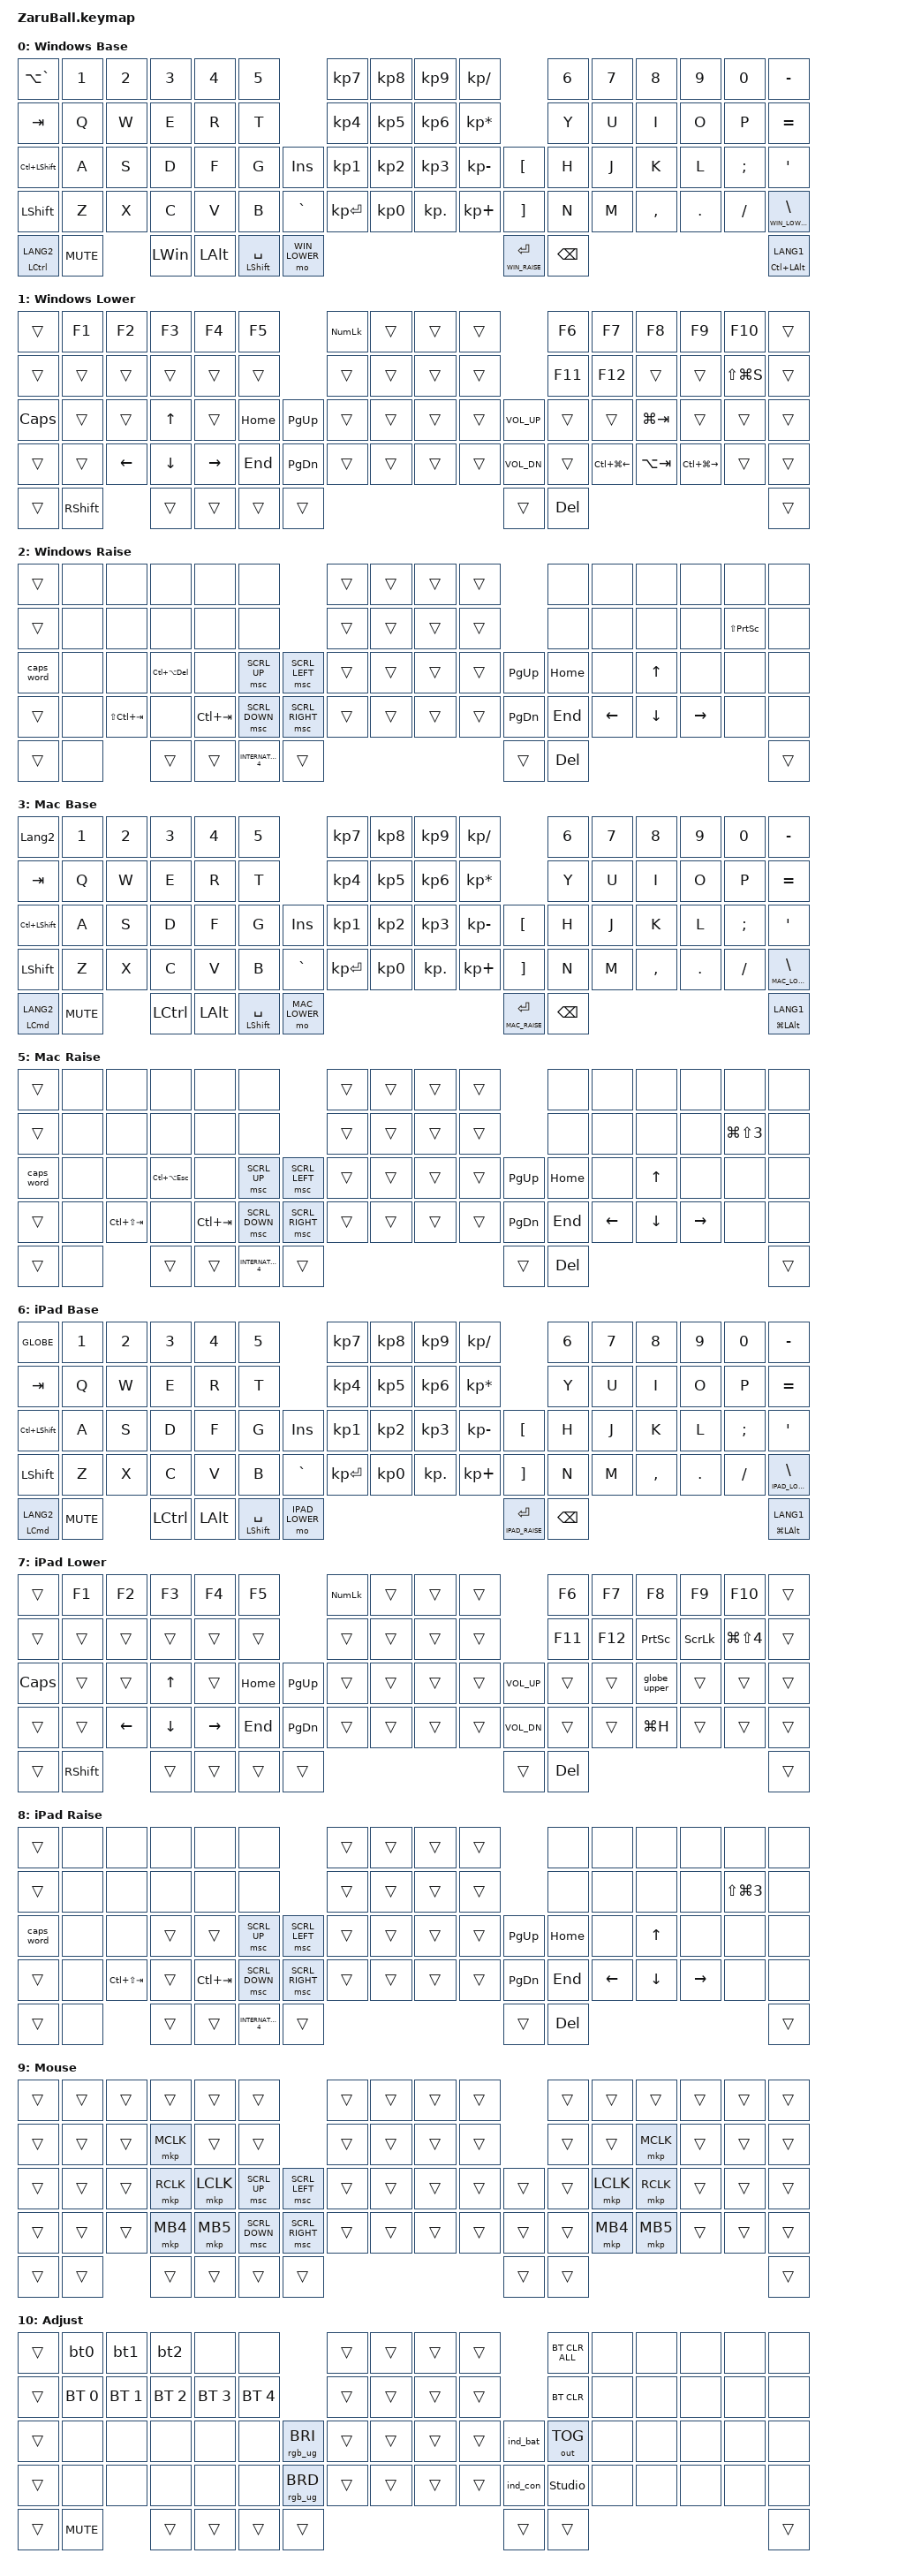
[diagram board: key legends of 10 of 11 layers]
//#include <dt-bindings/zmk/mouse.h>

#include <behaviors/rgbled_widget.dtsi>
#include <input/processors.dtsi>
#include <dt-bindings/zmk/input_transform.h>
#include <behaviors.dtsi>
#include <dt-bindings/zmk/bt.h>
#include <dt-bindings/zmk/keys.h>
#include <dt-bindings/zmk/outputs.h>
#include <dt-bindings/zmk/pointing.h>
#include <dt-bindings/zmk/rgb.h>

// Define LAYER

#define WIN_BASE    0
#define WIN_LOWER   1
#define WIN_RAISE   2
#define MAC_BASE    3
#define MAC_LOWER   4
#define MAC_RAISE   5
#define IPAD_BASE   6
#define IPAD_LOWER  7
#define IPAD_RAISE  8
#define MOUSE       9
#define ADJUST      10

// スクロール量の設定

#define ZMK_POINTING_DEFAULT_SCRL_VAL 100

/ {
    conditional_layers { compatible = "zmk,conditional-layers"; };
};

&trackball_listener {
    input-processors = <
                         &zip_xy_transform (INPUT_TRANSFORM_XY_SWAP | INPUT_TRANSFORM_Y_INVERT | INPUT_TRANSFORM_X_INVERT)
                         &zip_temp_layer MOUSE 100000
    >;

    scroller {
        layers = <WIN_LOWER WIN_RAISE MAC_LOWER MAC_RAISE IPAD_LOWER IPAD_RAISE ADJUST>;
        input-processors = <
                            &zip_xy_transform (INPUT_TRANSFORM_XY_SWAP | INPUT_TRANSFORM_X_INVERT)
                            &zip_xy_scaler 1 9
                            &zip_xy_to_scroll_mapper
        >;
    };
};

&mkp_input_listener { input-processors = <&zip_temp_layer MOUSE 250>; };

// You can find key number by entering config/info.json into https://zmk-physical-layout-converter.streamlit.app/

&zip_temp_layer {
    require-prior-idle-ms = <200>;
    excluded-positions = <
        19 // E
        28 // I
        35 // D
        36 // F
        37 // G
        38 // INS
        45 // J
        46 // K
        53 // C
        54 // V
        55 // B
        56 // GRAVE
        63 // M
    >;
};

/ {
    behaviors {
        // スクロール用のbehaviorの設定

        scroll_down_up: behavior_sensor_rotate_mouse_wheel_down_up {
            compatible = "zmk,behavior-sensor-rotate";
            #sensor-binding-cells = <0>;
            bindings = <&msc SCRL_DOWN>, <&msc SCRL_UP>;

            tap-ms = <20>; // スクロールのタップ時間
        };

        // Customed Hold-Tap for SandS

        SandS: SandS {
            compatible = "zmk,behavior-hold-tap";
            #binding-cells = <2>;
            flavor = "tap-unless-interrupted";
            tapping-term-ms = <500>;
            quick-tap-ms = <500>;
            bindings = <&kp>, <&kp>;

            display-name = "SandS";
        };

        // Ref: https://zenn.dev/shakupan/articles/261ce435251607

        tog_on: toggle_layer_on_only {
            compatible = "zmk,behavior-toggle-layer";
            #binding-cells = <1>;
            display-name = "Toggle Layer On";
            toggle-mode = "on";
        };

        tog_off: toggle_layer_off_only {
            compatible = "zmk,behavior-toggle-layer";
            #binding-cells = <1>;
            display-name = "Toggle Layer Off";
            toggle-mode = "off";
        };
    };
};

/ {
    macros {
        bt0: bt0 {
            compatible = "zmk,behavior-macro";
            #binding-cells = <0>;
            bindings =
                <&tog_off MAC_BASE &tog_off IPAD_BASE>,
                <&macro_wait_time 200>,
                <&bt BT_SEL 0>;

            label = "BT0";
            wait-ms = <200>;
        };

        bt1: bt1 {
            compatible = "zmk,behavior-macro";
            #binding-cells = <0>;
            bindings =
                <&tog_off MAC_BASE &tog_off IPAD_BASE>,
                <&macro_wait_time 200>,
                <&bt BT_SEL 1>,
                <&macro_wait_time 500>,
                <&tog_on MAC_BASE>;

            label = "BT1";
            wait-ms = <200>;
        };

        bt2: bt2 {
            compatible = "zmk,behavior-macro";
            #binding-cells = <0>;
            bindings =
                <&tog_off MAC_BASE &tog_off IPAD_BASE>,
                <&macro_wait_time 200>,
                <&bt BT_SEL 2>,
                <&macro_wait_time 500>,
                <&tog_on IPAD_BASE>;

            label = "BT2";
            wait-ms = <200>;
        };

        lalt_grave: lalt_grave {
            compatible = "zmk,behavior-macro";
            #binding-cells = <0>;
            bindings =
                <&kt LEFT_ALT>,
                <&macro_wait_time 10>,
                <&kp GRAVE &kt LEFT_ALT>;

            label = "LALT_GRAVE";
        };

        globe_upper: globe_upper {
            compatible = "zmk,behavior-macro";
            #binding-cells = <0>;
            bindings =
                <&kt GLOBE>,
                <&macro_wait_time 10>,
                <&kp UP_ARROW &kt GLOBE>;

            label = "GLOBE_UPPER";
        };
    };
};

/ {
    combos {
        compatible = "zmk,combos";

        ESCandToAdjustLayer {
            bindings = <&lt ADJUST ESC>;
            key-positions = <73 74>;
        };
    };

    keymap {
        compatible = "zmk,keymap";

        win_base {
            display-name = "Windows Base";
            sensor-bindings = <&scroll_down_up>;
            bindings = <
&kp LA(GRAVE)       &kp N1      &kp N2  &kp N3    &kp N4        &kp N5                                    &kp KP_N7     &kp KP_N8  &kp KP_N9   &kp KP_DIVIDE                         &kp NUMBER_6  &kp N7  &kp N8     &kp N9   &kp N0    &kp MINUS
&kp TAB             &kp Q       &kp W   &kp E     &kp R         &kp T                                     &kp KP_N4     &kp KP_N5  &kp KP_N6   &kp KP_MULTIPLY                       &kp Y         &kp U   &kp I      &kp O    &kp P     &kp EQUAL
&kp LC(LEFT_SHIFT)  &kp A       &kp S   &kp D     &kp F         &kp G                    &kp INS          &kp KP_N1     &kp KP_N2  &kp KP_N3   &kp KP_MINUS       &kp LEFT_BRACKET   &kp H         &kp J   &kp K      &kp L    &kp SEMI  &kp APOS
&kp LSHFT           &kp Z       &kp X   &kp C     &kp V         &kp B                    &kp GRAVE        &kp KP_ENTER  &kp KP_N0  &kp KP_DOT  &kp KP_PLUS        &kp RIGHT_BRACKET  &kp N         &kp M   &kp COMMA  &kp DOT  &kp FSLH  &lt WIN_LOWER BACKSLASH
&SandS LCTRL LANG2  &kp C_MUTE          &kp LWIN  &kp LEFT_ALT  &SandS LEFT_SHIFT SPACE  &mo WIN_LOWER                                                            &lt WIN_RAISE RET  &kp BSPC                                            &SandS LC(LEFT_ALT) LANG1
            >;
        };

        win_lower {
            display-name = "Windows Lower";
            sensor-bindings = <&inc_dec_kp C_VOL_UP C_VOL_DN>;
            bindings = <
&trans    &kp F1     &kp F2    &kp F3    &kp F4     &kp F5                 &kp KP_NUMLOCK  &trans  &trans  &trans                  &kp F6   &kp F7                  &kp F8       &kp F9                   &kp F10        &trans
&trans    &trans     &trans    &trans    &trans     &trans                 &trans          &trans  &trans  &trans                  &kp F11  &kp F12                 &trans       &trans                   &kp LS(LG(S))  &trans
&kp CAPS  &trans     &trans    &kp UP    &trans     &kp HOME  &kp PG_UP    &trans          &trans  &trans  &trans    &kp C_VOL_UP  &trans   &trans                  &kp LG(TAB)  &trans                   &trans         &trans
&trans    &trans     &kp LEFT  &kp DOWN  &kp RIGHT  &kp END   &kp PG_DN    &trans          &trans  &trans  &trans    &kp C_VOL_DN  &trans   &kp LC(LG(LEFT_ARROW))  &kp LA(TAB)  &kp LC(LG(RIGHT_ARROW))  &trans         &trans
&trans    &kp RSHFT            &trans    &trans     &trans    &trans                                                 &trans        &kp DEL                                                                               &trans
            >;
        };

        win_raise {
            display-name = "Windows Raise";
            sensor-bindings = <&inc_dec_kp RIGHT LEFT>;
            bindings = <
&trans      &none  &none            &none            &none        &none                                   &trans  &trans  &trans  &trans               &none     &none     &none     &none      &none          &none
&trans      &none  &none            &none            &none        &none                                   &trans  &trans  &trans  &trans               &none     &none     &none     &none      &kp LS(PSCRN)  &none
&caps_word  &none  &none            &kp LC(LA(DEL))  &none        &msc SCRL_UP         &msc SCRL_LEFT     &trans  &trans  &trans  &trans    &kp PG_UP  &kp HOME  &none     &kp UP    &none      &none          &none
&trans      &none  &kp LS(LC(TAB))  &none            &kp LC(TAB)  &msc SCRL_DOWN       &msc SCRL_RIGHT    &trans  &trans  &trans  &trans    &kp PG_DN  &kp END   &kp LEFT  &kp DOWN  &kp RIGHT  &none          &none
&trans      &none                   &trans           &trans       &kp INTERNATIONAL_4  &trans                                               &trans     &kp DEL                                                 &trans
            >;
        };

        mac_base {
            display-name = "Mac Base";
            sensor-bindings = <&scroll_down_up>;
            bindings = <
&kp LANGUAGE_2          &kp N1      &kp N2  &kp N3            &kp N4        &kp N5                                    &kp KP_N7     &kp KP_N8  &kp KP_N9   &kp KP_DIVIDE                         &kp NUMBER_6  &kp N7  &kp N8     &kp N9   &kp N0    &kp MINUS
&kp TAB                 &kp Q       &kp W   &kp E             &kp R         &kp T                                     &kp KP_N4     &kp KP_N5  &kp KP_N6   &kp KP_MULTIPLY                       &kp Y         &kp U   &kp I      &kp O    &kp P     &kp EQUAL
&kp LC(LEFT_SHIFT)      &kp A       &kp S   &kp D             &kp F         &kp G                    &kp INS          &kp KP_N1     &kp KP_N2  &kp KP_N3   &kp KP_MINUS       &kp LEFT_BRACKET   &kp H         &kp J   &kp K      &kp L    &kp SEMI  &kp APOS
&kp LSHFT               &kp Z       &kp X   &kp C             &kp V         &kp B                    &kp GRAVE        &kp KP_ENTER  &kp KP_N0  &kp KP_DOT  &kp KP_PLUS        &kp RIGHT_BRACKET  &kp N         &kp M   &kp COMMA  &kp DOT  &kp FSLH  &lt MAC_LOWER BACKSLASH
&mt LEFT_COMMAND LANG2  &kp C_MUTE          &kp LEFT_CONTROL  &kp LEFT_ALT  &SandS LEFT_SHIFT SPACE  &mo MAC_LOWER                                                            &lt MAC_RAISE RET  &kp BSPC                                            &mt LG(LEFT_ALT) LANG1
            >;
        };

        mac_lower {
            display-name = "Mac Lower";
            bindings = <
&kp LANGUAGE_1  &kp F1     &kp F2                &kp F3    &kp F4     &kp F5                 &kp KP_NUMLOCK  &trans  &trans  &trans                  &kp F6   &kp F7        &kp F8            &kp F9                &kp F10                   &trans
&trans          &trans     &kp LG(LS(NUMBER_4))  &trans    &trans     &trans                 &trans          &trans  &trans  &trans                  &kp F11  &kp F12       &trans            &kp LS(LG(NUMBER_4))  &kp LS(LG(LC(NUMBER_4)))  &trans
&kp CAPS        &trans     &trans                &kp UP    &trans     &kp HOME  &kp PG_UP    &trans          &trans  &trans  &trans    &kp C_VOL_UP  &trans   &trans        &kp LC(UP_ARROW)  &trans                &trans                    &trans
&trans          &trans     &kp LEFT              &kp DOWN  &kp RIGHT  &kp END   &kp PG_DN    &trans          &trans  &trans  &trans    &kp C_VOL_DN  &trans   &kp LC(LEFT)  &kp LC(DOWN)      &kp LC(RIGHT)         &trans                    &trans
&trans          &kp RSHFT                        &trans    &trans     &trans    &trans                                                 &trans        &kp DEL                                                                                  &trans
            >;

            sensor-bindings = <&inc_dec_kp C_VOL_UP C_VOL_DN>;
        };

        mac_raise {
            display-name = "Mac Raise";
            bindings = <
&trans      &none  &none            &none               &none        &none                                   &trans  &trans  &trans  &trans               &none     &none     &none     &none      &none                 &none
&trans      &none  &none            &none               &none        &none                                   &trans  &trans  &trans  &trans               &none     &none     &none     &none      &kp LG(LS(NUMBER_3))  &none
&caps_word  &none  &none            &kp LC(LA(ESCAPE))  &none        &msc SCRL_UP         &msc SCRL_LEFT     &trans  &trans  &trans  &trans    &kp PG_UP  &kp HOME  &none     &kp UP    &none      &none                 &none
&trans      &none  &kp LC(LS(TAB))  &none               &kp LC(TAB)  &msc SCRL_DOWN       &msc SCRL_RIGHT    &trans  &trans  &trans  &trans    &kp PG_DN  &kp END   &kp LEFT  &kp DOWN  &kp RIGHT  &none                 &none
&trans      &none                   &trans              &trans       &kp INTERNATIONAL_4  &trans                                               &trans     &kp DEL                                                        &trans
            >;

            sensor-bindings = <&inc_dec_kp RIGHT LEFT>;
        };

        ipad_base {
            display-name = "iPad Base";
            sensor-bindings = <&scroll_down_up>;
            bindings = <
&kp GLOBE               &kp N1      &kp N2  &kp N3            &kp N4        &kp N5                                     &kp KP_N7     &kp KP_N8  &kp KP_N9   &kp KP_DIVIDE                          &kp NUMBER_6  &kp N7  &kp N8     &kp N9   &kp N0    &kp MINUS
&kp TAB                 &kp Q       &kp W   &kp E             &kp R         &kp T                                      &kp KP_N4     &kp KP_N5  &kp KP_N6   &kp KP_MULTIPLY                        &kp Y         &kp U   &kp I      &kp O    &kp P     &kp EQUAL
&kp LC(LEFT_SHIFT)      &kp A       &kp S   &kp D             &kp F         &kp G                    &kp INS           &kp KP_N1     &kp KP_N2  &kp KP_N3   &kp KP_MINUS       &kp LEFT_BRACKET    &kp H         &kp J   &kp K      &kp L    &kp SEMI  &kp APOS
&kp LSHFT               &kp Z       &kp X   &kp C             &kp V         &kp B                    &kp GRAVE         &kp KP_ENTER  &kp KP_N0  &kp KP_DOT  &kp KP_PLUS        &kp RIGHT_BRACKET   &kp N         &kp M   &kp COMMA  &kp DOT  &kp FSLH  &lt IPAD_LOWER BACKSLASH
&mt LEFT_COMMAND LANG2  &kp C_MUTE          &kp LEFT_CONTROL  &kp LEFT_ALT  &SandS LEFT_SHIFT SPACE  &mo IPAD_LOWER                                                            &lt IPAD_RAISE RET  &kp BSPC                                            &mt LG(LEFT_ALT) LANG1
            >;
        };

        ipad_lower {
            display-name = "iPad Lower";
            bindings = <
&trans    &kp F1     &kp F2    &kp F3    &kp F4     &kp F5                 &kp KP_NUMLOCK  &trans  &trans  &trans                  &kp F6   &kp F7   &kp F8           &kp F9          &kp F10               &trans
&trans    &trans     &trans    &trans    &trans     &trans                 &trans          &trans  &trans  &trans                  &kp F11  &kp F12  &kp PRINTSCREEN  &kp SCROLLLOCK  &kp LG(LS(NUMBER_4))  &trans
&kp CAPS  &trans     &trans    &kp UP    &trans     &kp HOME  &kp PG_UP    &trans          &trans  &trans  &trans    &kp C_VOL_UP  &trans   &trans   &globe_upper     &trans          &trans                &trans
&trans    &trans     &kp LEFT  &kp DOWN  &kp RIGHT  &kp END   &kp PG_DN    &trans          &trans  &trans  &trans    &kp C_VOL_DN  &trans   &trans   &kp LG(H)        &trans          &trans                &trans
&trans    &kp RSHFT            &trans    &trans     &trans    &trans                                                 &trans        &kp DEL                                                                  &trans
            >;

            sensor-bindings = <&inc_dec_kp C_VOL_UP C_VOL_DN>;
        };

        ipad_raise {
            display-name = "iPad Raise";
            bindings = <
&trans      &none  &none            &none   &none        &none                                   &trans  &trans  &trans  &trans               &none     &none     &none     &none      &none                 &none
&trans      &none  &none            &none   &none        &none                                   &trans  &trans  &trans  &trans               &none     &none     &none     &none      &kp LS(LG(NUMBER_3))  &none
&caps_word  &none  &none            &trans  &trans       &msc SCRL_UP         &msc SCRL_LEFT     &trans  &trans  &trans  &trans    &kp PG_UP  &kp HOME  &none     &kp UP    &none      &none                 &none
&trans      &none  &kp LC(LS(TAB))  &trans  &kp LC(TAB)  &msc SCRL_DOWN       &msc SCRL_RIGHT    &trans  &trans  &trans  &trans    &kp PG_DN  &kp END   &kp LEFT  &kp DOWN  &kp RIGHT  &none                 &none
&trans      &none                   &trans  &trans       &kp INTERNATIONAL_4  &trans                                               &trans     &kp DEL                                                        &trans
            >;

            sensor-bindings = <&inc_dec_kp RIGHT LEFT>;
        };

        mouse_layer {
            display-name = "Mouse";
            sensor-bindings = <&scroll_down_up>;
            bindings = <
&trans  &trans  &trans  &trans     &trans     &trans                             &trans  &trans  &trans  &trans            &trans  &trans     &trans     &trans  &trans  &trans
&trans  &trans  &trans  &mkp MCLK  &trans     &trans                             &trans  &trans  &trans  &trans            &trans  &trans     &mkp MCLK  &trans  &trans  &trans
&trans  &trans  &trans  &mkp RCLK  &mkp LCLK  &msc SCRL_UP    &msc SCRL_LEFT     &trans  &trans  &trans  &trans    &trans  &trans  &mkp LCLK  &mkp RCLK  &trans  &trans  &trans
&trans  &trans  &trans  &mkp MB4   &mkp MB5   &msc SCRL_DOWN  &msc SCRL_RIGHT    &trans  &trans  &trans  &trans    &trans  &trans  &mkp MB4   &mkp MB5   &trans  &trans  &trans
&trans  &trans          &trans     &trans     &trans          &trans                                               &trans  &trans                                        &trans
            >;
        };

        adjust_layer {
            display-name = "Adjust";
            sensor-bindings = <&inc_dec_kp C_VOL_UP C_VOL_DN>;
            bindings = <
&trans  &bt0          &bt1          &bt2          &none         &none                            &trans  &trans  &trans  &trans              &bt BT_CLR_ALL  &none  &none  &none  &none  &none
&trans  &bt BT_SEL 0  &bt BT_SEL 1  &bt BT_SEL 2  &bt BT_SEL 3  &bt BT_SEL 4                     &trans  &trans  &trans  &trans              &bt BT_CLR      &none  &none  &none  &none  &none
&trans  &none         &none         &none         &none         &none         &rgb_ug RGB_BRI    &trans  &trans  &trans  &trans    &ind_bat  &out OUT_TOG    &none  &none  &none  &none  &none
&trans  &none         &none         &none         &none         &none         &rgb_ug RGB_BRD    &trans  &trans  &trans  &trans    &ind_con  &studio_unlock  &none  &none  &none  &none  &none
&trans  &kp C_MUTE                  &trans        &trans        &trans        &trans                                               &trans    &trans                                      &trans
            >;
        };
    };
};
